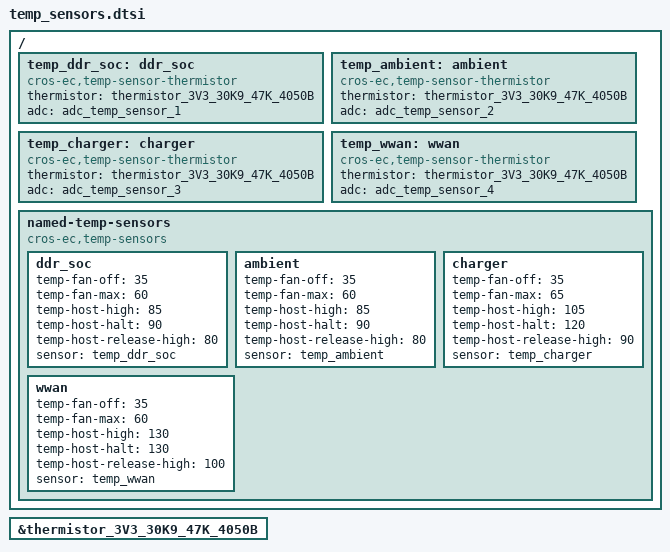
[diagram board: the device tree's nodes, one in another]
/* Copyright 2022 The ChromiumOS Authors
 * Use of this source code is governed by a BSD-style license that can be
 * found in the LICENSE file.
 */

#include <cros/thermistor/thermistor.dtsi>

/ {
	temp_ddr_soc: ddr_soc {
		compatible = "cros-ec,temp-sensor-thermistor";
		thermistor = <&thermistor_3V3_30K9_47K_4050B>;
		adc = <&adc_temp_sensor_1>;
	};
	temp_ambient: ambient {
		compatible = "cros-ec,temp-sensor-thermistor";
		thermistor = <&thermistor_3V3_30K9_47K_4050B>;
		adc = <&adc_temp_sensor_2>;
	};
	temp_charger: charger {
		compatible = "cros-ec,temp-sensor-thermistor";
		thermistor = <&thermistor_3V3_30K9_47K_4050B>;
		adc = <&adc_temp_sensor_3>;
	};
	temp_wwan: wwan {
		compatible = "cros-ec,temp-sensor-thermistor";
		thermistor = <&thermistor_3V3_30K9_47K_4050B>;
		adc = <&adc_temp_sensor_4>;
	};

	named-temp-sensors {
		compatible = "cros-ec,temp-sensors";
		ddr_soc {
			temp-fan-off = <35>;
			temp-fan-max = <60>;
			temp-host-high = <85>;
			temp-host-halt = <90>;
			temp-host-release-high = <80>;
			sensor = <&temp_ddr_soc>;
		};
		ambient {
			temp-fan-off = <35>;
			temp-fan-max = <60>;
			temp-host-high = <85>;
			temp-host-halt = <90>;
			temp-host-release-high = <80>;
			sensor = <&temp_ambient>;
		};
		charger {
			temp-fan-off = <35>;
			temp-fan-max = <65>;
			temp-host-high = <105>;
			temp-host-halt = <120>;
			temp-host-release-high = <90>;
			sensor = <&temp_charger>;
		};
		wwan {
			temp-fan-off = <35>;
			temp-fan-max = <60>;
			temp-host-high = <130>;
			temp-host-halt = <130>;
			temp-host-release-high = <100>;
			sensor = <&temp_wwan>;
		};
	};
};

&thermistor_3V3_30K9_47K_4050B {
	status = "okay";
};
